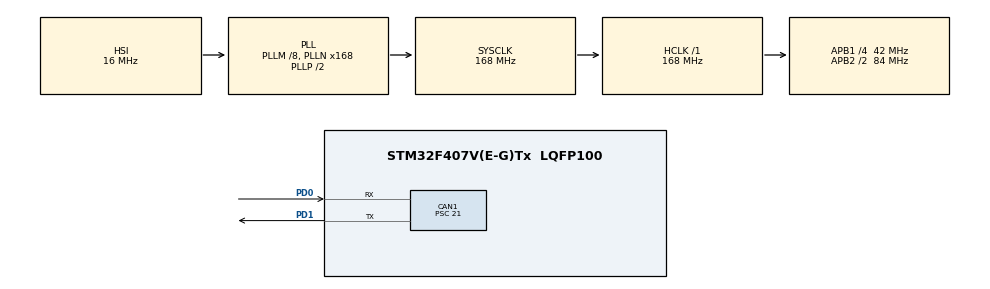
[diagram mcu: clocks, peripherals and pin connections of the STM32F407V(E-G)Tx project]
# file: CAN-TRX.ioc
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CAN1.ABOM=ENABLE
CAN1.AWUM=ENABLE
CAN1.BS1=CAN_BS1_13TQ
CAN1.BS2=CAN_BS2_2TQ
CAN1.CalculateBaudRate=125000
CAN1.CalculateTimeBit=8000.00
CAN1.CalculateTimeQuantum=500.0
CAN1.NART=ENABLE
CAN1.Prescaler=21
Mcu.Family=STM32F4
Mcu.Name=STM32F407V(E-G)Tx
Mcu.Package=LQFP100
NVIC.CAN1_RX0_IRQn=true\:0\:0\:false\:false\:true\:true\:true
NVIC.CAN1_RX1_IRQn=true\:0\:0\:false\:false\:true\:true\:true
NVIC.CAN1_SCE_IRQn=true\:0\:0\:false\:false\:true\:true\:true
NVIC.CAN1_TX_IRQn=true\:0\:0\:false\:false\:true\:true\:true
NVIC.PriorityGroup=NVIC_PRIORITYGROUP_4
PD0.Mode=CAN_Activate
PD0.Signal=CAN1_RX
PD1.Mode=CAN_Activate
PD1.Signal=CAN1_TX
ProjectManager.HeapSize=0x200
ProjectManager.StackSize=0x400
ProjectManager.TargetToolchain=MDK-ARM V5.27
RCC.48MHZClocksFreq_Value=84000000
RCC.AHBFreq_Value=168000000
RCC.APB1CLKDivider=RCC_HCLK_DIV4
RCC.APB1Freq_Value=42000000
RCC.APB1TimFreq_Value=84000000
RCC.APB2CLKDivider=RCC_HCLK_DIV2
RCC.APB2Freq_Value=84000000
RCC.APB2TimFreq_Value=168000000
RCC.CortexFreq_Value=168000000
RCC.HCLKFreq_Value=168000000
RCC.HSE_VALUE=25000000
RCC.HSI_VALUE=16000000
RCC.LSE_VALUE=32768
RCC.PLLM=8
RCC.PLLN=168
RCC.SYSCLKFreq_VALUE=168000000
RCC.SYSCLKSource=RCC_SYSCLKSOURCE_PLLCLK
RCC.VCOOutputFreq_Value=336000000
board=custom

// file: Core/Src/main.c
/* USER CODE BEGIN Header */
/**
  ******************************************************************************
  * @file           : main.c
  * @brief          : Main program body
  ******************************************************************************
  * @attention
  *
  * <h2><center>&copy; Copyright (c) 2024 STMicroelectronics.
  * All rights reserved.</center></h2>
  *
  * This software component is licensed by ST under BSD 3-Clause license,
  * the "License"; You may not use this file except in compliance with the
  * License. You may obtain a copy of the License at:
  *                        opensource.org/licenses/BSD-3-Clause
  *
  ******************************************************************************
  */
/* USER CODE END Header */
#include "main.h"
#include "can.h"
#include "gpio.h"

/* USER CODE BEGIN Includes */
#include "ALCD.h"
/* USER CODE END Includes */

/* USER CODE BEGIN PTD */
typedef struct {
  uint32_t      Timestamp;
  uint32_t      Counter;
} CAN_Frame;
/* USER CODE END PTD */

/* USER CODE BEGIN PV */

// CAN Tx Variables
static CAN_TxHeaderTypeDef    txHeader;
static CAN_Frame              txFrame = {0};

// CAN Rx Variables
static CAN_RxHeaderTypeDef    rxHeader;
static CAN_Frame              rxFrame;
static uint8_t                rxFlag = 0;
/* USER CODE END PV */

void SystemClock_Config(void);

int main(void)
{
  /* USER CODE BEGIN 1 */
  uint32_t nextSend = 0;
  /* USER CODE END 1 */

  /* MCU Configuration--------------------------------------------------------*/

  /* Reset of all peripherals, Initializes the Flash interface and the Systick. */
  HAL_Init();

  /* Configure the system clock */
  SystemClock_Config();

  /* Initialize all configured peripherals */
  MX_GPIO_Init();
  MX_CAN1_Init();
  /* USER CODE BEGIN 2 */
  ALCD_init(16, 2);
  ALCD_clear();
  /* USER CODE END 2 */

  /* Infinite loop */
  /* USER CODE BEGIN WHILE */
  while (1)
  {
    // CAN Send - Tx
    if (nextSend <= HAL_GetTick()) {
      nextSend = HAL_GetTick() + 1000;
      // Fill Tx Header
      txHeader.StdId = 0x514;
      txHeader.IDE = CAN_ID_STD;
      txHeader.DLC = sizeof(txFrame);
      // Fill Data Frame
      txFrame.Timestamp = HAL_GetTick();
      txFrame.Counter++;
      // Send to mailbox
      uint32_t txMailbox;
      HAL_CAN_AddTxMessage(&hcan1, &txHeader, (uint8_t*) &txFrame, &txMailbox);
      // Display on ALCD
      ALCD_printfXY(0, 0, "T: %03X %-6u", txHeader.StdId, txFrame.Counter);
    }

    // CAN Receive - Rx
    if (rxFlag) {
      rxFlag = 0;
      // Display on ALCD
      ALCD_printfXY(0, 1, "R: %03X %-6u", rxHeader.StdId, rxFrame.Counter);
    }

    /* USER CODE END WHILE */

  }
}

void SystemClock_Config(void)
{
  RCC_OscInitTypeDef RCC_OscInitStruct = {0};
  RCC_ClkInitTypeDef RCC_ClkInitStruct = {0};

  /** Configure the main internal regulator output voltage
  */
  __HAL_RCC_PWR_CLK_ENABLE();
  __HAL_PWR_VOLTAGESCALING_CONFIG(PWR_REGULATOR_VOLTAGE_SCALE1);
  /** Initializes the RCC Oscillators according to the specified parameters
  * in the RCC_OscInitTypeDef structure.
  */
  RCC_OscInitStruct.OscillatorType = RCC_OSCILLATORTYPE_HSI;
  RCC_OscInitStruct.HSIState = RCC_HSI_ON;
  RCC_OscInitStruct.HSICalibrationValue = RCC_HSICALIBRATION_DEFAULT;
  RCC_OscInitStruct.PLL.PLLState = RCC_PLL_ON;
  RCC_OscInitStruct.PLL.PLLSource = RCC_PLLSOURCE_HSI;
  RCC_OscInitStruct.PLL.PLLM = 8;
  RCC_OscInitStruct.PLL.PLLN = 168;
  RCC_OscInitStruct.PLL.PLLP = RCC_PLLP_DIV2;
  RCC_OscInitStruct.PLL.PLLQ = 4;
  if (HAL_RCC_OscConfig(&RCC_OscInitStruct) != HAL_OK)
  {
    Error_Handler();
  }
  /** Initializes the CPU, AHB and APB buses clocks
  */
  RCC_ClkInitStruct.ClockType = RCC_CLOCKTYPE_HCLK|RCC_CLOCKTYPE_SYSCLK
                              |RCC_CLOCKTYPE_PCLK1|RCC_CLOCKTYPE_PCLK2;
  RCC_ClkInitStruct.SYSCLKSource = RCC_SYSCLKSOURCE_PLLCLK;
  RCC_ClkInitStruct.AHBCLKDivider = RCC_SYSCLK_DIV1;
  RCC_ClkInitStruct.APB1CLKDivider = RCC_HCLK_DIV4;
  RCC_ClkInitStruct.APB2CLKDivider = RCC_HCLK_DIV2;

  if (HAL_RCC_ClockConfig(&RCC_ClkInitStruct, FLASH_LATENCY_5) != HAL_OK)
  {
    Error_Handler();
  }
}

/* USER CODE BEGIN 4 */
void HAL_CAN_RxFifo0MsgPendingCallback(CAN_HandleTypeDef* hcan) {
  HAL_CAN_GetRxMessage(hcan, CAN_FILTER_FIFO0, &rxHeader, (uint8_t*) &rxFrame);
  rxFlag = 1;
}
/* USER CODE END 4 */

void Error_Handler(void)
{
  __disable_irq();
  while (1)
  {
  }
}

/************************ (C) COPYRIGHT STMicroelectronics *****END OF FILE****/
